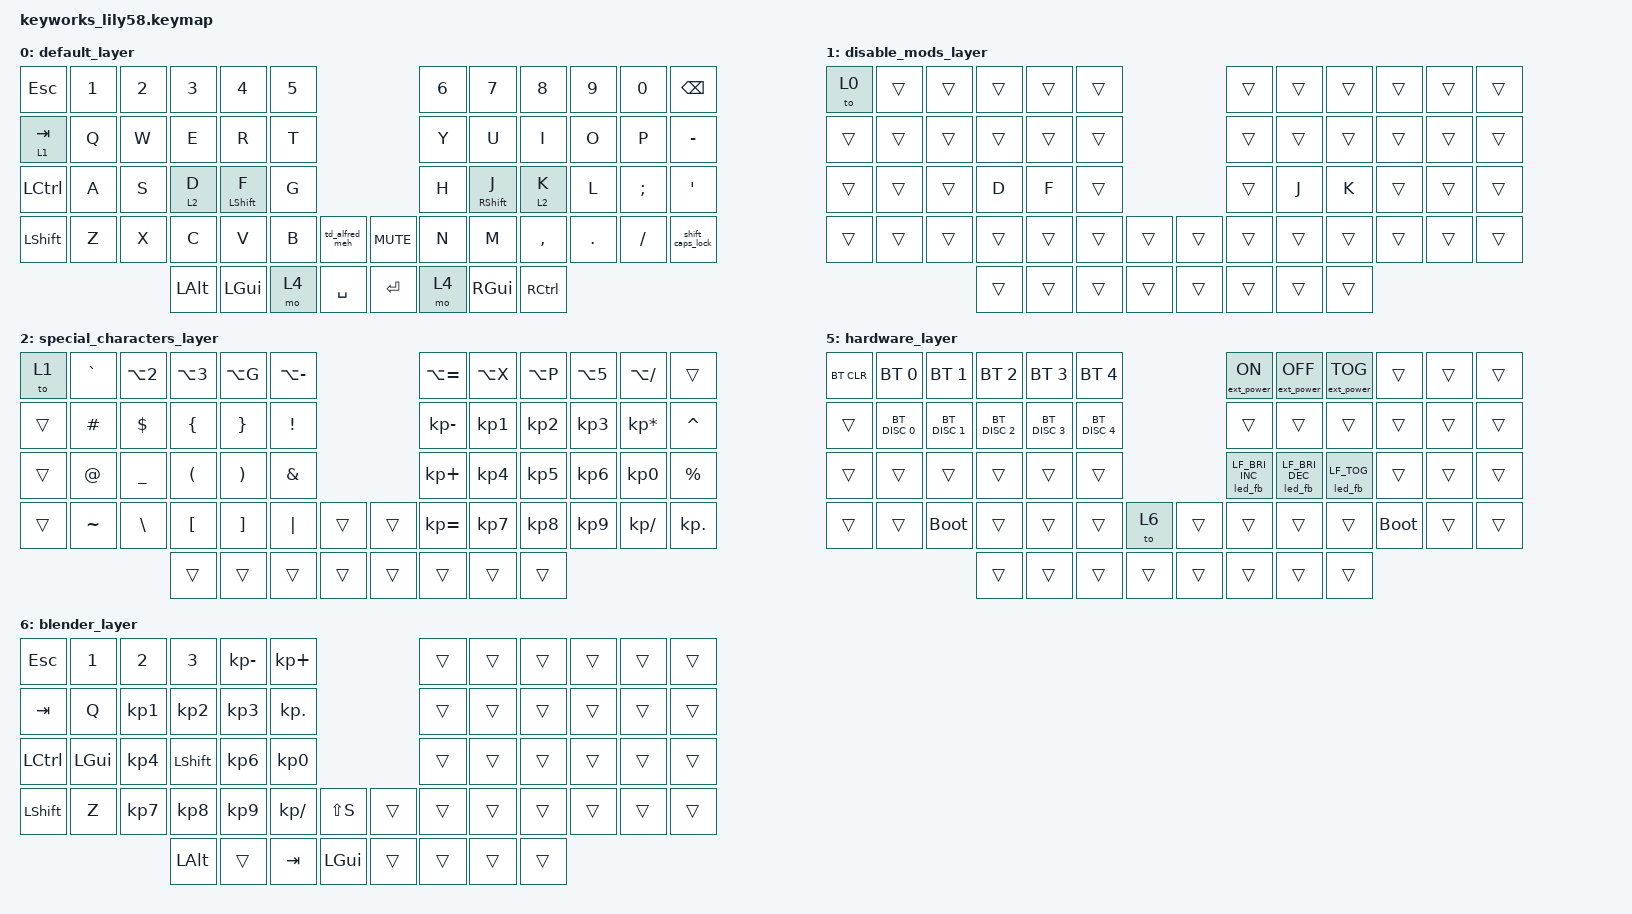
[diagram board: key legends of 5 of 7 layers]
/*
 * Copyright (c) 2022 The ZMK Contributors
 *
 * SPDX-License-Identifier: MIT
 */

#include <behaviors.dtsi>
#include <dt-bindings/zmk/bt.h>
#include <dt-bindings/zmk/ext_power.h>
#include <dt-bindings/zmk/keys.h>
#include <dt-bindings/zmk/led_feedback.h>

#include "mouse.dtsi"

// Defining Left and right hand keys (Lily58)
#define KEYS_L 0 1 2 3 4 5 12 13 14 15 16 17 24 25 26 27 28 29 36 37 38 39 40 41 50 51 52 53 42
#define KEYS_R 6 7 8 9 10 11 18 19 20 21 22 23 30 31 32 33 34 35 44 45 46 47 48 49 54 55 56 57 43

//  Key positions (for use in combo's etc...) 
//  0  1  2  3  4  5            6  7  8  9  10 11
//  12 13 14 15 16 17           18 19 20 21 22 23
//  24 25 26 27 28 29           30 31 32 33 34 35
//  36 37 38 39 40 41 42     43 44 45 46 47 48 49
//           50 51 52 53     54 55 56 57

// Layers
// Layers can be changed/toggled with a tap or hold key presses and with combos.

// Go down one layer with ESC
// Layer 0 (tap)(Combo)(toggle) : 0 and 36
// Layer 2 (hold)               : 27 or 32
// Layer 3 (hold)(Combo)        : 27 and 28
// Layer 3 (hold)(Combo)        : 31 and 32
// Layer 3 (tap)(Combo)(toggle) : 24 and 35
// Layer 4 (tap)                : 52 or 55
// Layer 5 (hold)(Combo)        : 52 and 24
// Layer 5 (hold)(Combo)        : 55 and 24

// Bootloader Mode
// For the left side, activate bootloader mode by holding layer 5 and typing `X` (position 38)
// For the right side, activate bootloader mode by holding layer 5 and typing `.` (position 47)

// Caps Word
// https://zmk.dev/docs/keymaps/behaviors/caps-word
&caps_word {
    continue-list = <UNDERSCORE MINUS BACKSPACE DELETE SPACE>;
};

/ {
    behaviors {

        // LED brightness (zmk-led-feedback module)
        led_fb: led_feedback {
            compatible = "zmk,behavior-led-feedback";
            #binding-cells = <1>;
        };

        // Battery level of a peripheral: 1 = first LED number, 2 = second, 0 = all
        led_bat: led_feedback_battery {
            compatible = "zmk,behavior-led-feedback-battery";
            #binding-cells = <1>;
        };

        // Layer Tap
        //https://zmk.dev/docs/keymaps/behaviors/hold-tap#layer-tap

        // Left (home row) momentary layer 2 change
        left_hand_LT: left_hand_LT {
            compatible = "zmk,behavior-hold-tap";
            label = "LEFT_HAND_LT";
            bindings = <&mo>, <&kp>;

            #binding-cells = <2>;
            hold-trigger-key-positions = <KEYS_R>;
            tapping-term-ms = <280>;
            hold-trigger-on-release;
            require-prior-idle-ms = <150>;
            flavor = "balanced";
            quick-tap-ms = <175>;
        };

        // Right (home row) momentary layer 2 change
        right_hand_LT: right_hand_LT {
            compatible = "zmk,behavior-hold-tap";
            label = "RIGHT_HAND_LT";
            bindings = <&mo>, <&kp>;

            #binding-cells = <2>;
            tapping-term-ms = <280>;
            hold-trigger-key-positions = <KEYS_L>;
            quick-tap-ms = <175>;
            require-prior-idle-ms = <150>;
            flavor = "balanced";
            hold-trigger-on-release;
        };

        // Momentary Layer
        // https://zmk.dev/docs/keymaps/behaviors/layers#momentary-layer

        // Left (home row) Shift
        left_hand_MT: left_hand_MT {
            compatible = "zmk,behavior-hold-tap";
            label = "LEFT_HAND_MT";
            bindings = <&kp>, <&kp>;

            #binding-cells = <2>;
            hold-trigger-key-positions = <KEYS_R>;
            tapping-term-ms = <280>;
            hold-trigger-on-release;
            require-prior-idle-ms = <150>;
            flavor = "balanced";
            quick-tap-ms = <175>;
        };

        // Right (home row) Shift
        right_hand_MT: right_hand_MT {
            compatible = "zmk,behavior-hold-tap";
            label = "RIGHT_HAND_MT";
            bindings = <&kp>, <&kp>;

            #binding-cells = <2>;
            tapping-term-ms = <280>;
            hold-trigger-key-positions = <KEYS_L>;
            quick-tap-ms = <175>;
            require-prior-idle-ms = <150>;
            flavor = "balanced";
            hold-trigger-on-release;
        };

        // Tap dance
        // https://zmk.dev/docs/keymaps/behaviors/tap-dance

        // Tab dance 1: Shift - 2: Caps Word (see above)
        shift_caps_lock: shift_caps_lock {
            compatible = "zmk,behavior-tap-dance";
            #binding-cells = <0>;
            tapping-term-ms = <250>;
            bindings = <&kp RSHFT>, <&caps_word>;
        };

        // Tab dance 1aunch Alfred app - 2: sticky MEH key combination
        // https://zmkv/docs/keymaps/behaviors/sticky-key
        td_alfred_meh: tap_dance_alfred_meh {
            compatible = "zmk,behavior-tap-dance";
            #binding-cells = <0>;
            tapping-term-ms = <200>;
            bindings = <&alfred>, <&sticky_meh>;
        };

    };

    // Combos
    // https://zmk.dev/docs/keymaps/combos

    combos {
        compatible = "zmk,combos";
        
        // Open apps with alfred
        combo_meh_left {
            bindings = <&kp LS(LA(LEFT_CONTROL))>;
            key-positions = <52 51 50>;
        };
        // Open apps with alfred
        combo_meh_right {
            bindings = <&kp LS(LA(LEFT_CONTROL))>;
            key-positions = <55 56 57>;
        };
        // same as above
        combo_meh_action_keys {
            bindings = <&kp LS(LA(LEFT_CONTROL))>;
            key-positions = <52 55>;
        };
        // L Shift + Escape: Toggle layer 0 combo
        combo_escape_to_default_layer {
            bindings = <&to 0>;
            key-positions = <36 0>;
        };
        // L CTRL + ': Toggle layer 3 combo
        combo_toggle_mouse_layer {
            bindings = <&to 3>;
            key-positions = <24 35>;
        };
        // D + F: Momentary layer 3 combo
        combo_momentary_mouse_layer_right {
            bindings = <&mo 3>;
            key-positions = <27 28>;
        };
        // J + K: Momentary layer 3 combo
        combo_momentary_mouse_layer_left {
            bindings = <&mo 3>;
            key-positions = <31 32>;
        };

        // ctrl + shift: show layer on dongle left
        combo_dongle_layer_left {
            bindings = <&led_fb LF_LAYER>;
            key-positions = <36 24>;
        };

        // shift + ': show layer on dongle right
        combo_dongle_layer_right {
            bindings = <&led_fb LF_LAYER>;
            key-positions = <49 35>;
        };
    };


    macros {
        // Switch to layer 0 before using Homerow app
        howmerow: howmerow {
            compatible = "zmk,behavior-macro";
            #binding-cells = <0>;
            bindings
                = <&macro_press &to 0>
                , <&macro_release &to 0>
                ,<&macro_press &kp ESC>
                , <&macro_release &kp ESC>
                ,<&macro_press &kp LS(LG(SPACE))>
                , <&macro_release &kp LS(LG(SPACE))>
                ;
        };
        // Switch to layer 0 before using Alfred app
        alfred: alfred {
            compatible = "zmk,behavior-macro";
            #binding-cells = <0>;
            bindings
                = <&macro_press &to 0>
                , <&macro_release &to 0>
                ,<&macro_press &kp LA(SPACE)>
                , <&macro_release &kp LA(SPACE)>
                ;
        };

        // Switch to layer 0 before using sticky MEH
        sticky_meh: sticky_meh {
            compatible = "zmk,behavior-macro";
            #binding-cells = <0>;
            bindings
                = <&macro_press &to 0>
                , <&macro_release &to 0>
                ,<&macro_press &sk LS(LA(LEFT_CONTROL))>
                , <&macro_release  &sk LS(LA(LEFT_CONTROL))>
                ;
        };

        // Set window to specific size (1400 x 1080) and move to center
        // Mac Shortcuts app is used to resize and move windows
        // Alfred is used to fire the Shortcuts
        windowsize: windowsize {
            compatible = "zmk,behavior-macro";
            #binding-cells = <0>;
            wait-ms = <150>;
            bindings
                = <&macro_press &kp LS(LA(LC(U)))>
                , <&macro_release &kp LS(LA(LC(U)))>
                ,<&macro_press &kp LS(LA(LC(Y)))>
                , <&macro_release &kp LS(LA(LC(Y)))>
                ,<&macro_press &kp LS(LA(LC(I)))>
                , <&macro_release &kp LS(LA(LC(I)))>
                ;
        };

        // macOS: go to top of page/window, then return to layer 0
        page_top_layer0: page_top_layer0 {
            compatible = "zmk,behavior-macro";
            #binding-cells = <0>;
            bindings
            = <&macro_press &kp LG(UP)>
            , <&macro_release &kp LG(UP)>
                , <&macro_press &to 0>
                , <&macro_release &to 0>
                ;
        };

        // macOS: go to bottom of page/window, then return to layer 0
        page_bottom_layer0: page_bottom_layer0 {
            compatible = "zmk,behavior-macro";
            #binding-cells = <0>;
            bindings
            = <&macro_press &kp LG(DOWN)>
            , <&macro_release &kp LG(DOWN)>
                , <&macro_press &to 0>
                , <&macro_release &to 0>
                ;
        };
    };


    keymap {
        compatible = "zmk,keymap";

        // Layer (0). Default layer with minimal home row mods
        // TD = tap dance

        // Hold f or j to activate shift
        // Hold d or k to momentary activate the special characters layer (2)
        // Momentary activate the action (4) and mouse (3) layers from this layer
        // Hit escape to get back to this layer (if you've toggled to another layer)
        default_layer {
            // ╭──────────────────────────────────────────────────────────╮                                    ╭───────────────────────────────────────────────────────────────────────────────────╮
            // │ ESC   │  1  │  2  │  3           │  4         │  5       │                                    │  6       │  7          │  8           │  9  │  0  │ BKSPC                         │
            // │ TAB   │  Q  │  W  │  E           │  R         │  T       │                                    │  Y       │  U          │  I           │  O  │  P  │   -                           │
            // │ CTRL  │  A  │  S  │  D / Layer 2 │  F / SHIFT │  G       ╰────────────────────────╮  ╭────────╯  H       │  J  / SHIFT │  K / Layer 2 │  L  │  ;  │   '                           │
            // │ SHIFT │  Z  │  X  │  C           │  V         │  B       │ TD1: Alfred - TD2: MEH │  │ Mute   │  N       │  M          │  ,           │  .  │  /  │ TD 1: Shift - TD 2: Caps Lock │
            // ╰───────────────────╮  ALT         │  GUI       │  Layer 4 │ SPACE                  │  │ ENTER  │  Layer 4 │  GUI        │  CTRL        ╭───────────────────────────────────────────╯
            //                     ╰───────────────────────────────────────────────────────────────╯  ╰────────────────────────────────────────────────╯

            bindings = <
&kp ESC        &kp N1  &kp N2  &kp N3             &kp N4                      &kp N5                                &kp N6  &kp N7                        &kp N8              &kp N9   &kp N0    &kp BSPC
&lt 1 TAB        &kp Q   &kp W   &kp E              &kp R                       &kp T                                 &kp Y   &kp U                         &kp I               &kp O    &kp P     &kp MINUS
&kp LCTRL      &kp A   &kp S   &left_hand_LT 2 D  &left_hand_MT LEFT_SHIFT F  &kp G                                 &kp H   &right_hand_MT RIGHT_SHIFT J  &right_hand_LT 2 K  &kp L    &kp SEMI  &kp SQT
&kp LSHFT      &kp Z   &kp X   &kp C              &kp V                       &kp B   &td_alfred_meh    &kp C_MUTE  &kp N   &kp M                         &kp COMMA           &kp DOT  &kp FSLH  &shift_caps_lock
                               &kp LALT           &kp LGUI                    &mo 4   &kp SPACE         &kp ENTER   &mo 4   &kp RGUI                      &kp RCTRL
            >;

            sensor-bindings = <&inc_dec_kp C_VOL_UP C_VOL_DN &inc_dec_kp C_VOL_DN C_VOL_UP>;
        };

        // Layer (1). Disable home row mods for testing
        // To get to this layer toggle the mouse layer (3) with a combo (combo_toggle_mouse_layer) and hit escape until you're on this layer
        disable_mods_layer {
            // ╭────────────────────────────────────╮              ╭───────────────────────────────────╮
            // │  L0  │     │     │     │     │     │              │     │     │     │     │     │     │
            // │      │     │     │     │     │     │              │     │     │     │     │     │     │
            // │      │     │     │  D  │  F  │     ╰─────╮  ╭─────╯     │  J  │  K  │     │     │     │
            // │      │     │     │     │     │     │     │  │     │     │     │     │     │     │     │
            // ╰──────────────────╮     │     │     │     │  │     │     │     │     ╭─────────────────╯
            //                    ╰───────────────────────╯  ╰───────────────────────╯

            bindings = <
&to  0  &trans  &trans  &trans  &trans  &trans                    &trans  &trans  &trans  &trans  &trans  &trans
&trans  &trans  &trans  &trans  &trans  &trans                    &trans  &trans  &trans  &trans  &trans  &trans
&trans  &trans  &trans  &kp D   &kp F   &trans                    &trans  &kp J   &kp K   &trans  &trans  &trans
&trans  &trans  &trans  &trans  &trans  &trans  &trans    &trans  &trans  &trans  &trans  &trans  &trans  &trans
                        &trans  &trans  &trans  &trans    &trans  &trans  &trans  &trans
            >;

            sensor-bindings = <&inc_dec_kp C_VOL_UP C_VOL_DN &inc_dec_kp C_VOL_DN C_VOL_UP>;
        };

        // Layer (2). Special characters layer
        // To get to this layer use the home row mods (key d or k) or toggle the mouse layer (3) and hit escape until you're on this layer
        special_characters_layer {
            // ╭────────────────────────────────────╮              ╭───────────────────────────────────╮
            // │  L1  │  `  │  €  │  £  │  ©  │  –  │              │  ≠  │  ≈  │  π  │  ∞  │  ÷  │     │
            // │      │  #  │  $  │  {  │  }  │  !  │              │  -  │  1  │  2  │  3  │  *  │  ^  │
            // │      │  @  │  _  │  (  │  )  │  &  ╰─────╮  ╭─────╯  +  │  4  │  5  │  6  │  0  │  %  │
            // │      │  ~  │  \  │  [  │  ]  │  |  │     │  │     │  =  │  7  │  8  │  9  │  /  │  .  │
            // ╰──────────────────╮     │     │     │     │  │     │     │     │     ╭─────────────────╯
            //                    ╰───────────────────────╯  ╰───────────────────────╯

            bindings = <
&to 1   &kp GRAVE  &kp LA(N2)  &kp LA(N3)  &kp LA(G)  &kp LA(MINUS)                    &kp LA(EQUAL)  &kp LA(X)  &kp LA(P)  &kp LA(N5)  &kp LA(SLASH)    &trans
&trans  &kp HASH   &kp DOLLAR  &kp LBRC    &kp RBRC   &kp EXCL                         &kp KP_MINUS   &kp KP_N1  &kp KP_N2  &kp KP_N3   &kp KP_MULTIPLY  &kp CARET
&trans  &kp AT     &kp UNDER   &kp LPAR    &kp RPAR   &kp AMPS                         &kp KP_PLUS    &kp KP_N4  &kp KP_N5  &kp KP_N6   &kp KP_N0        &kp PRCNT
&trans  &kp TILDE  &kp BSLH    &kp LBKT    &kp RBKT   &kp PIPE       &trans    &trans  &kp KP_EQUAL   &kp KP_N7  &kp KP_N8  &kp KP_N9   &kp KP_SLASH     &kp KP_DOT
                               &trans      &trans     &trans         &trans    &trans  &trans         &trans     &trans
            >;

            sensor-bindings = <&inc_dec_kp C_VOL_UP C_VOL_DN &inc_dec_kp C_VOL_DN C_VOL_UP>;
        };

        // Layer (3). Mouse and scroll movements
        // To toggle the mouse layer, momentary activate the action layer (4) and hit shift at the same time
        mouse_layer {
            // ╭─────────────────────────────────────────────────────────────────────────────────────────────────────────────────╮              ╭───────────────────────────────────────────────────────────────────╮
            // │  L2  │ focus menu bar          │ focus status        │ focus window toolbar │                      │ focus dock │              │          │          │          │          │ toggle L0 │           │
            // │  L0  │ dongle on               │ dongle brightness + │ dongle battery left  │ dongle battery right │ top        │              │ scroll v │  L click │ mouse ∧  │ R click  │           │ scroll v  │
            // │      │ dongle off              │ dongle brightness - │                      │ dongle battery both  │ bottom     ╰─────╮  ╭─────╯ scroll ∧ │  < mouse │ mouse v  │ mouse >  │           │ scroll ∧  │
            // │      │ dongle layer continuous │                     │                      │                      │            │     │  │     │          │ scroll > │ < scroll │ < scroll │           │           │
            // ╰──────────────────────────────────────────────────────╮                      │                      │            │     │  │     │          │          │          ╭──────────────────────────────────╯
            //                                                        ╰────────────────────────────────────────────────────────────────╯  ╰──────────────────────────────────────╯


            bindings = <
&to 2   &kp LC(F2)            &kp LC(F8)          &kp LC(F5)  &trans          &kp LC(F3)                           &trans          &trans           &trans          &trans           &to 0   &trans
&to 0   &led_fb LF_ON         &led_fb LF_BRI_INC  &led_bat 1  &led_bat 2      &page_top_layer0                     &msc SCRL_DOWN  &mkp MB1         &mmv MOVE_UP    &mkp MB2         &trans  &msc SCRL_DOWN
&trans  &led_fb LF_OFF        &led_fb LF_BRI_DEC  &trans      &led_bat 0      &page_bottom_layer0                  &msc SCRL_UP    &mmv MOVE_LEFT   &mmv MOVE_DOWN  &mmv MOVE_RIGHT  &trans  &msc SCRL_UP
&trans  &led_fb LF_LAYER_TOG  &led_fb LF_TOG       &trans      &trans          &trans               &trans  &trans  &msc SCRL_UP    &msc SCRL_RIGHT  &msc SCRL_LEFT  &msc SCRL_LEFT   &trans  &trans
                                                  &trans      &trans          &trans               &trans  &trans  &trans          &trans
            >;

            sensor-bindings = <&inc_dec_kp C_VOL_UP C_VOL_DN &inc_dec_kp C_VOL_DN C_VOL_UP>;
        };

    // Layer (4). Action layer
    action_layer {
            // ╭───────────────────────────────────────────────────────────────────────────────────╮                ╭───────────────────────────────────────────────────────────────────╮
            // │ undo      │ brightness + │ brightness - │ mission ctrl │ launchpad │ windowsize   │                │ prev     │ pause/play │   next   │ mute     │ vol -   │ vol +     │
            // │ redo      │ cmd Q        │ cmd W        │ esc          │ hypr R    │ zoom +       │                │ scroll v │     < hist │     ∧    │ hist >   │         │ scroll v  │
            // │ L5        │ control      │ alt          │ L gui        │ L shft    │ zoom -       ╰───────╮  ╭─────╯ scroll ∧ │          < │     v    │ >        │ Finder  │ scroll ∧  │
            // │ toggle L3 │ < window     │ window >     │ wndw full    │ wndw cntr │ zoom 0       │ cmd ~ │  │     │ < tab    │      tab > │ < mv tab │ mv tab > │         │ toggle L3 │
            // ╰─────────────────────────────────────────╮              │           │              │       │  │     │          │            │          ╭────────────────────────────────╯
            //                                           ╰─────────────────────────────────────────────────╯  ╰────────────────────────────────────────╯

            bindings = <
&kp LG(Z)      &kp C_BRI_DN              &kp C_BRI_UP               &kp LC(UP)             &kp LS(LC(LA(LG(L))))  &windowsize                            &kp C_PREV       &kp C_PP           &kp C_NEXT         &kp C_MUTE         &kp C_VOL_DN       &kp C_VOL_UP
&kp LG(LS(Z))  &kp LG(Q)                 &kp LG(W)                  &kp ESCAPE             &howmerow              &kp LG(EQUAL)                          &msc SCRL_DOWN    &kp LG(LBKT)       &kp UP             &kp LG(RBKT)       &trans             &msc SCRL_DOWN
&mo 5          &kp LCTRL                 &kp LALT                   &kp LGUI               &kp LSHFT              &kp LG(MINUS)                          &msc SCRL_UP      &kp LEFT           &kp DOWN           &kp RIGHT          &kp LS(LA(LC(F)))  &msc SCRL_UP
&to 3          &kp LS(LC(LA(LG(LEFT))))  &kp LS(LC(LA(LG(RIGHT))))  &kp LS(LC(LA(LG(F))))  &kp LG(LS(C))          &kp LG(N0)     &kp LG(GRAVE)   &trans  &kp LA(LG(LEFT))  &kp LA(LG(RIGHT))  &kp RC(RS(PG_UP))  &kp RC(RS(PG_DN))  &trans             &to 3
                                                                    &trans                 &trans                 &trans         &trans          &trans  &trans            &trans             &trans
            >;

            sensor-bindings = <&inc_dec_kp C_VOL_UP C_VOL_DN &inc_dec_kp C_VOL_DN C_VOL_UP>;
        };

        // Layer (5). Connect and Disconnect bluetooth profiles
        // To get to this layer, momentary activate the action layer (4) and hit the backspace key on the left half of the keyboard
        hardware_layer {
            // ╭───────────────────────────────────────────────────────────────────────────────────╮              ╭─────────────────────────────────────────────────────────────╮
            // │ BT CLR │ conn BT 1    │ conn BT 2    │ conn BT 3    │ conn BT 4    │ conn BT 5    │              │ vcc pwr on │ vcc pwr off │ vcc pwr toggle │     │     │     │
            // │        │ disconn BT 1 │ disconn BT 2 │ disconn BT 3 │ disconn BT 4 │ disconn BT 5 │              │            │             │                │     │     │     │
            // │        │              │              │              │              │              ╰─────╮  ╭─────╯            │             │                │     │     │     │
            // │        │              │              │              │              │              │ L6  │  │     │            │             │                │     │     │     │
            // ╰──────────────────────────────────────╮              │              │              │     │  │     │            │             │                ╭─────────────────╯
            //                                        ╰──────────────────────────────────────────────────╯  ╰─────────────────────────────────────────────────╯

            bindings = <
&bt BT_CLR  &bt BT_SEL 0   &bt BT_SEL 1   &bt BT_SEL 2   &bt BT_SEL 3   &bt BT_SEL 4                    &ext_power EP_ON  &ext_power EP_OFF  &ext_power EP_TOG  &trans       &trans  &trans
&trans      &bt BT_DISC 0  &bt BT_DISC 1  &bt BT_DISC 2  &bt BT_DISC 3  &bt BT_DISC 4                   &trans            &trans             &trans             &trans       &trans  &trans
&trans      &trans         &trans         &trans         &trans         &trans                          &led_fb LF_BRI_INC  &led_fb LF_BRI_DEC  &led_fb LF_TOG  &trans       &trans  &trans
&trans      &trans         &bootloader    &trans         &trans         &trans        &to 6     &trans  &trans            &trans             &trans             &bootloader  &trans  &trans
                                          &trans         &trans         &trans        &trans    &trans  &trans            &trans             &trans
            >;

            sensor-bindings = <&inc_dec_kp C_VOL_UP C_VOL_DN &inc_dec_kp C_VOL_DN C_VOL_UP>;
        };
        // Layer (6). Blender
        // To get out of this layer press shift and escape together
        blender_layer {
            // ╭──────────────────────────────────────────────────╮                   ╭───────────────────────────────────╮
            // │ ESC   │  1   │  2     │  3      │  np -  │ np +  │                   │     │     │     │     │     │     │
            // │ TAB   │  Q   │  np 1  │  np 2   │  np 3  │ np .  │                   │     │     │     │     │     │     │
            // │ CTRL  │ LGUI │  np 4  │  SHIFT  │  np 6  │ np 0  ╰──────────╮  ╭─────╯     │     │     │     │     │     │
            // │ SHIFT │  Z   │  np 7  │  np 8   │  np 9  │ np /  │ SHIFT S  │  │     │     │     │     │     │     │     │
            // ╰───────────────────────╮  ALT    │        │ TAB   │ LGUI     │  │     │     │     │     ╭─────────────────╯
            //                         ╰─────────────────────────────────────╯  ╰───────────────────────╯

            bindings = <
&kp ESC    &kp N1    &kp N2     &kp N3     &kp KP_MINUS   &kp KP_PLUS                         &trans  &trans  &trans  &trans  &trans  &trans
&kp TAB    &kp Q     &kp KP_N1  &kp KP_N2  &kp KP_N3      &kp KP_DOT                          &trans  &trans  &trans  &trans  &trans  &trans
&kp LCTRL  &kp LGUI  &kp KP_N4  &kp LSHFT  &kp KP_N6      &kp KP_N0                           &trans  &trans  &trans  &trans  &trans  &trans
&kp LSHFT  &kp Z     &kp KP_N7  &kp KP_N8  &kp KP_N9      &kp KP_SLASH &kp LS(S)      &trans  &trans  &trans  &trans  &trans  &trans  &trans
                                &kp LALT   &trans         &kp TAB      &kp LGUI       &trans  &trans  &trans  &trans
            >;

            sensor-bindings = <&inc_dec_kp C_VOL_UP C_VOL_DN &inc_dec_kp C_VOL_DN C_VOL_UP>;
        };
    };
};

// Empty for copy paste
// ╭───────────────────────────────────╮              ╭───────────────────────────────────╮
// │     │     │     │     │     │     │              │     │     │     │     │     │     │
// │     │     │     │     │     │     │              │     │     │     │     │     │     │
// │     │     │     │     │     │     ╰─────╮  ╭─────╯     │     │     │     │     │     │
// │     │     │     │     │     │     │     │  │     │     │     │     │     │     │     │
// ╰─────────────────╮     │     │     │     │  │     │     │     │     ╭─────────────────╯
//                   ╰───────────────────────╯  ╰───────────────────────╯
